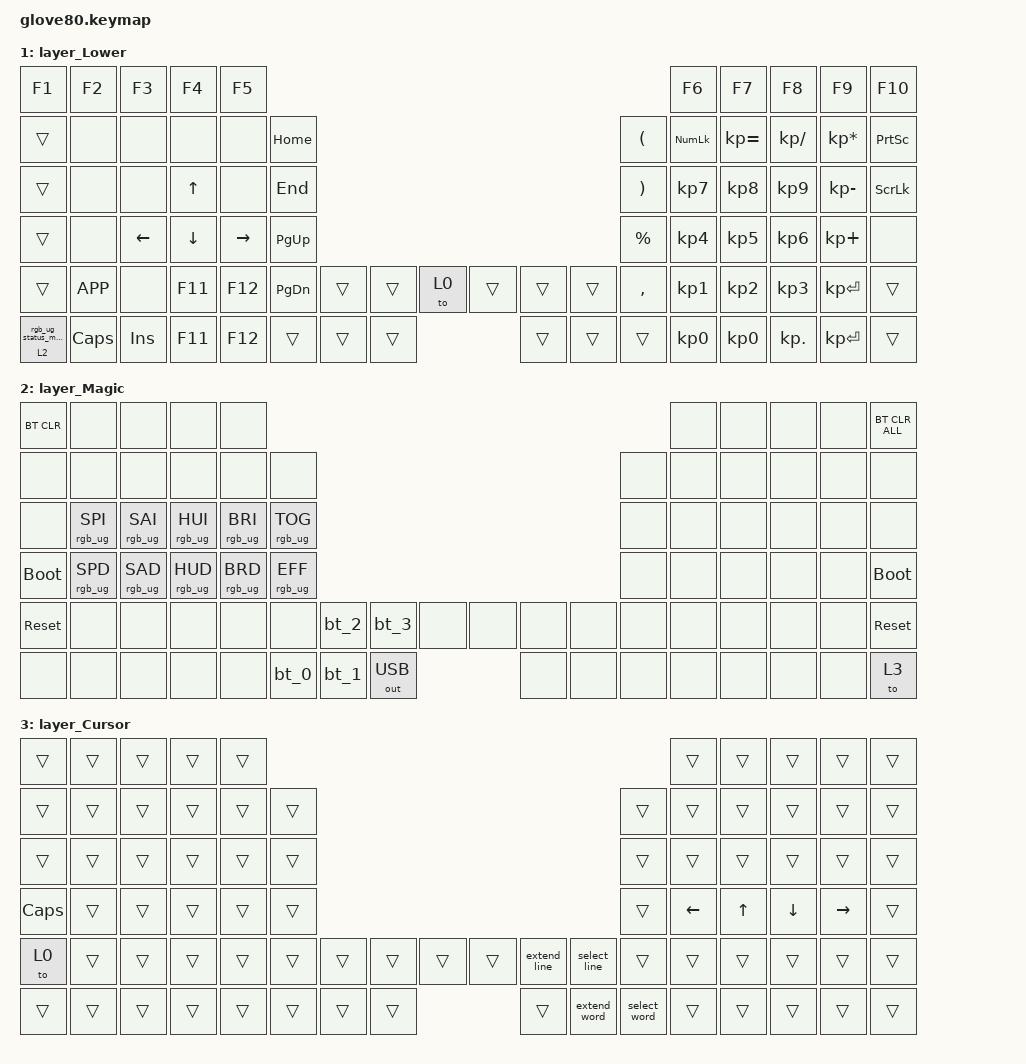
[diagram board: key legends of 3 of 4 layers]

/*
 * Copyright (c) 2020 The ZMK Contributors
 * Copyright (c) 2022 Innaworks Development Limited, trading as MoErgo
 *
 * SPDX-License-Identifier: MIT
 */


/* THIS FILE WAS GENERATED BY GLOVE80 LAYOUT EDITOR
 *
 * This file was generated automatically. You may or may not want to
 * edit it directly.
 */

#include <behaviors.dtsi>
/* Include all behaviour includes needed by system behaviors/macros */
#include <dt-bindings/zmk/outputs.h>

/* Include behaviour includes needed by key binds - automatically generated */
#include <dt-bindings/zmk/keys.h>
#include <dt-bindings/zmk/ext_power.h>
#include <dt-bindings/zmk/bt.h>
#include <dt-bindings/zmk/outputs.h>
#include <dt-bindings/zmk/rgb.h>


    /* Custom Defined Behaviors */
    //
    // Glove80 key positions index for positional hold-tap
    // https://discord.com/channels/877392805654306816/937645688244826154/1066713913351221248
    // https://media.discordapp.net/attachments/937645688244826154/1066713913133121556/image.png
    //
    // |------------------------|------------------------|
    // | LEFT_HAND_KEYS         |        RIGHT_HAND_KEYS |
    // |                        |                        |
    // |  0  1  2  3  4         |          5  6  7  8  9 |
    // | 10 11 12 13 14 15      |      16 17 18 19 20 21 |
    // | 22 23 24 25 26 27      |      28 29 30 31 32 33 |
    // | 34 35 36 37 38 39      |      40 41 42 43 44 45 |
    // | 46 47 48 49 50 51      |      58 59 60 61 62 63 |
    // | 64 65 66 67 68         |         75 76 77 78 79 |
    // |                69 52   |   57 74                |
    // |                 70 53  |  56 73                 |
    // |                  71 54 | 55 72                  |
    // |------------------------|------------------------|
    //
    //
    #define LEFT_HAND_KEYS      \
          0  1  2  3  4         \
         10 11 12 13 14 15      \
         22 23 24 25 26 27      \
         34 35 36 37 38 39      \
         46 47 48 49 50 51      \
         64 65 66 67 68
    #define                              RIGHT_HAND_KEYS \
                                           5  6  7  8  9 \
                                       16 17 18 19 20 21 \
                                       28 29 30 31 32 33 \
                                       40 41 42 43 44 45 \
                                       58 59 60 61 62 63 \
                                          75 76 77 78 79
    #define THUMB_KEYS          \
                        69 52       57 74                \
                         70 53     56 73                 \
                          71 54   55 72

/ {
combos {
    compatible = "zmk,combos";
    combo_space {
        timeout-ms = <50>;
        key-positions = <69 70>;
        bindings = <&kp SPACE>;
    };
    combo_enter {
        timeout-ms = <50>;
        key-positions = <70 71>;
        bindings = <&kp ENTER>;
    };
    combo_tab {
        timeout-ms = <50>;
        key-positions = <52 69>;
        bindings = <&kp TAB>;
    };
};
behaviors {
    magic: magic_hold_tap {
        compatible = "zmk,behavior-hold-tap";
        label = "MAGIC_HOLD_TAP";
        #binding-cells = <2>;
        flavor = "tap-preferred";
        tapping-term-ms = <200>;
        bindings = <&mo>, <&rgb_ug_status_macro>;
    };
            // For the "layer" key, it'd nice to be able to use it as either a shift or a toggle.
        // Configure it as a tap dance, so the first tap (or hold) is a &mo and the second tap is a &to
        lower: tap_dance_0 {
            compatible = "zmk,behavior-tap-dance";
            label = "LAYER_TAP_DANCE";
            #binding-cells = <0>;
            tapping-term-ms = <200>;
            bindings = <&mo 1>, <&to 1>;
        };

gqt2: global-quick-tap2 {
    compatible = "zmk,behavior-hold-tap";
    flavor = "tap-preferred";
    label = "HOME_ROW_MODS_PINKY_GUI2";
    #binding-cells = <2>;
    bindings = <&gravey>, <&kp>;
    tapping-term-ms = <320>; // extra delay
    quick-tap-ms = <160>;
    global-quick-tap;
};

    behavior_caps_word {
        continue-list = <UNDERSCORE MINUS BACKSPACE DELETE N1 N2 N3 N4 N5 N6 N7 N8 N9 N0>;
    };

    cappy: caps_word_lock {
        compatible = "zmk,behavior-mod-morph";
        label = "CAPS_WORD_LOCK";
        #binding-cells = <0>;
        bindings = <&caps_word>, <&kp CAPSLOCK>;
        mods = <(MOD_LSFT|MOD_RSFT)>;
    };

// Miryoku home row mods and thumb key layers
// https://sunaku.github.io/home-row-mods.html
    homey_left: home_row_mods_left_hand {
        compatible = "zmk,behavior-hold-tap";
        flavor = "tap-preferred";
        label = "HOME_ROW_MODS_LEFT_HAND";
        #binding-cells = <2>;
        bindings = <&kp>, <&kp>;
        hold-trigger-key-positions = <RIGHT_HAND_KEYS THUMB_KEYS>;
        hold-trigger-on-release;
        tapping-term-ms = <250>;
        quick-tap-ms = <175>;
        global-quick-tap-ms = <150>;
    };

    homey_right: home_row_mods_right_hand {
        compatible = "zmk,behavior-hold-tap";
        flavor = "tap-preferred";
        label = "HOME_ROW_MODS_RIGHT_HAND";
        #binding-cells = <2>;
        bindings = <&kp>, <&kp>;
        hold-trigger-key-positions = <LEFT_HAND_KEYS THUMB_KEYS>;
        hold-trigger-on-release;
        tapping-term-ms = <250>;
        quick-tap-ms = <175>;
        global-quick-tap-ms = <150>;
    };



    index_left: home_row_mods_left_index_shift {
        compatible = "zmk,behavior-hold-tap";
        flavor = "tap-preferred";
        label = "HOME_ROW_MODS_LEFT_INDEX_SHIFT";
        #binding-cells = <2>;
        bindings = <&kp>, <&kp>;
        hold-trigger-key-positions = <RIGHT_HAND_KEYS THUMB_KEYS>;
        hold-trigger-on-release;
        tapping-term-ms = <200>;
        quick-tap-ms = <160>;
        //global-quick-tap; // no typing streak
    };

    index_right: home_row_mods_right_index_shift {
        compatible = "zmk,behavior-hold-tap";
        flavor = "tap-preferred";
        label = "HOME_ROW_MODS_RIGHT_INDEX_SHIFT";
        #binding-cells = <2>;
        bindings = <&kp>, <&kp>;
        hold-trigger-key-positions = <LEFT_HAND_KEYS THUMB_KEYS>;
        hold-trigger-on-release;
        tapping-term-ms = <200>;
        quick-tap-ms = <160>;
        //global-quick-tap; // no typing streak
    };

    pinky: home_row_mods_pinky_gui {
        compatible = "zmk,behavior-hold-tap";
        flavor = "tap-preferred";
        label = "HOME_ROW_MODS_PINKY_GUI";
        #binding-cells = <2>;
        bindings = <&kp>, <&kp>;
        tapping-term-ms = <320>; // extra delay
        quick-tap-ms = <175>;
        global-quick-tap-ms = <150>;
    };

    pinky_left: home_row_mods_left_pinky_gui {
        compatible = "zmk,behavior-hold-tap";
        flavor = "tap-preferred";
        label = "HOME_ROW_MODS_LEFT_PINKY_GUI";
        #binding-cells = <2>;
        bindings = <&kp>, <&kp>;
        hold-trigger-key-positions = <RIGHT_HAND_KEYS THUMB_KEYS>;
        hold-trigger-on-release;
        tapping-term-ms = <320>; // extra delay
        quick-tap-ms = <175>;
        global-quick-tap-ms = <150>;
    };

    pinky_right: home_row_mods_right_pinky_gui {
        compatible = "zmk,behavior-hold-tap";
        flavor = "tap-preferred";
        label = "HOME_ROW_MODS_RIGHT_PINKY_GUI";
        #binding-cells = <2>;
        bindings = <&kp>, <&kp>;
        hold-trigger-key-positions = <LEFT_HAND_KEYS THUMB_KEYS>;
        hold-trigger-on-release;
        tapping-term-ms = <320>; // extra delay
        quick-tap-ms = <175>;
        global-quick-tap-ms = <150>;
    };

    thumb: miryoku_thumb_layer {
        compatible = "zmk,behavior-hold-tap";
        label = "MIRYOKU_LAYER_TAP_WITH_REPEAT";
        #binding-cells = <2>;
        flavor = "balanced"; // faster hold-tap
        tapping-term-ms = <200>;
        quick-tap-ms = <200>; // enable repeat
        bindings = <&mo>, <&kp>;
    };
};

macros {


        rgb_ug_status_macro: rgb_ug_status_macro_0 {
            label = "RGB_UG_STATUS";
            compatible = "zmk,behavior-macro";
            #binding-cells = <0>;
            bindings
                = <&rgb_ug RGB_STATUS>;
        };
        bt_0: bt_profile_macro_0 {
            label = "BT_0";
            compatible = "zmk,behavior-macro";
            #binding-cells = <0>;
            bindings
                = <&out OUT_BLE>,
                  <&bt BT_SEL 0>;
        };
        bt_1: bt_profile_macro_1 {
            label = "BT_1";
            compatible = "zmk,behavior-macro";
            #binding-cells = <0>;
            bindings
                = <&out OUT_BLE>,
                  <&bt BT_SEL 1>;
        };
        bt_2: bt_profile_macro_2 {
            label = "BT_2";
            compatible = "zmk,behavior-macro";
            #binding-cells = <0>;
            bindings
                = <&out OUT_BLE>,
                  <&bt BT_SEL 2>;
        };

        bt_3: bt_profile_macro_3 {
            label = "BT_3";
            compatible = "zmk,behavior-macro";
            #binding-cells = <0>;
            bindings
                = <&out OUT_BLE>,
                  <&bt BT_SEL 3>;
        };


    gravey: gravey {
wait-ms = <10>;
        label = "gravey";
        compatible = "zmk,behavior-macro";
        #binding-cells = <0>;
        bindings
            = <&macro_tap &kp GRAVE &kp GRAVE &kp GRAVE &kp SPACE>;
    };

    // Approximation of Pascal Getreuer's SelectWord feature in QMK
    // https://getreuer.info/posts/keyboards/select-word/index.html
    select_word: select_word {
        compatible = "zmk,behavior-macro";
        label = "select_word";
        #binding-cells = <0>;
        tap-ms = <0>;
        wait-ms = <0>;
        bindings
        = <&macro_tap &kp LC(RIGHT)>
        , <&macro_wait_time 1> // let cursor move to the next word!
        , <&macro_tap &kp LC(LEFT) &kp LC(LS(RIGHT))>
        ;
    };
    extend_word: extend_word {
        compatible = "zmk,behavior-macro";
        label = "extend_word";
        #binding-cells = <0>;
        tap-ms = <0>;
        wait-ms = <0>;
        bindings
        = <&macro_tap &kp LC(LS(RIGHT))>
        ;
    };
    select_line: select_line {
        compatible = "zmk,behavior-macro";
        label = "select_line";
        #binding-cells = <0>;
        tap-ms = <0>;
        wait-ms = <0>;
        bindings
        = <&macro_tap &kp HOME &kp LS(END)>
        ;
    };
    extend_line: extend_line {
        compatible = "zmk,behavior-macro";
        label = "extend_line";
        #binding-cells = <0>;
        tap-ms = <0>;
        wait-ms = <0>;
        bindings
        = <&macro_tap &kp LS(DOWN) &kp LS(END)>
        ;
    };
};


    /* Automatically generated keymap */
    keymap {
        compatible = "zmk,keymap";


        layer_Base {
            bindings = <
        &kp C_BRI_DN         &kp C_BRI_UP          &kp C_PREV          &kp C_NEXT              &kp C_PP                                                                                              &kp C_MUTE             &kp C_VOL_DN           &kp C_VOL_UP                    &none      &kp PAUSE_BREAK
           &kp MINUS               &kp N1              &kp N2              &kp N3                &kp N4  &kp N5                                                                   &kp N6                 &kp N7                   &kp N8                 &kp N9                   &kp N0            &kp EQUAL
             &kp TAB                &kp Q               &kp W               &kp E                 &kp R   &kp T                                                                    &kp Y                  &kp U                    &kp I                  &kp O                    &kp P             &kp BSLH
              &cappy  &pinky_left LCTRL A  &homey_left LALT S  &homey_left LGUI D  &index_left LSHIFT F   &kp G                                                                    &kp H  &index_right LSHIFT J      &homey_right LGUI K    &homey_right LALT L  &pinky_right LCTRL SEMI  &pinky CAPSLOCK SQT
 &gqt2 &gravey GRAVE                &kp Z  &homey_left RALT X  &homey_left RGUI C                 &kp V   &kp B  &thumb 3 ESC   &kp UP  &kp DOWN  &kp LEFT  &kp RIGHT    &kp RET   &kp N                  &kp M  &homey_right RGUI COMMA  &homey_right RALT DOT                 &kp FSLH            &kp PG_UP
          &magic 2 0             &kp HOME             &kp END           &kp LG(C)             &kp LG(V)              &kp BSPC  &kp DEL    &lower    &lower    &kp TAB  &kp SPACE                        &kp INS                    &none               &kp LBKT                 &kp RBKT            &kp PG_DN
            >;
        };

        layer_Lower {
            bindings = <
     &kp F1     &kp F2          &kp F3          &kp F4           &kp F5                                                                                        &kp F6        &kp F7        &kp F8           &kp F9          &kp F10
     &trans      &none           &none           &none            &none   &kp HOME                                                   &kp LEFT_PARENTHESIS  &kp KP_NUM  &kp KP_EQUAL  &kp KP_SLASH  &kp KP_MULTIPLY  &kp PRINTSCREEN
     &trans      &none           &none    &kp UP_ARROW            &none    &kp END                                                  &kp RIGHT_PARENTHESIS   &kp KP_N7     &kp KP_N8     &kp KP_N9     &kp KP_MINUS   &kp SCROLLLOCK
     &trans      &none  &kp LEFT_ARROW  &kp DOWN_ARROW  &kp RIGHT_ARROW  &kp PG_UP                                                            &kp PERCENT   &kp KP_N4     &kp KP_N5     &kp KP_N6      &kp KP_PLUS            &none
     &trans  &kp K_APP           &none         &kp F11          &kp F12  &kp PG_DN  &trans  &trans   &to 0  &trans  &trans  &trans              &kp COMMA   &kp KP_N1     &kp KP_N2     &kp KP_N3     &kp KP_ENTER           &trans
 &magic 2 0   &kp CAPS         &kp INS         &kp F11          &kp F12             &trans  &trans  &trans  &trans  &trans  &trans                          &kp KP_N0     &kp KP_N0    &kp KP_DOT     &kp KP_ENTER           &trans
            >;
        };

        layer_Magic {
            bindings = <
  &bt BT_CLR            &none            &none            &none            &none                                                                                  &none   &none   &none   &none  &bt BT_CLR_ALL
       &none            &none            &none            &none            &none            &none                                                         &none   &none   &none   &none   &none           &none
       &none  &rgb_ug RGB_SPI  &rgb_ug RGB_SAI  &rgb_ug RGB_HUI  &rgb_ug RGB_BRI  &rgb_ug RGB_TOG                                                         &none   &none   &none   &none   &none           &none
 &bootloader  &rgb_ug RGB_SPD  &rgb_ug RGB_SAD  &rgb_ug RGB_HUD  &rgb_ug RGB_BRD  &rgb_ug RGB_EFF                                                         &none   &none   &none   &none   &none     &bootloader
      &sys_reset            &none            &none            &none            &none            &none   &bt_2   &bt_3         &none   &none   &none   &none   &none   &none   &none   &none   &none          &sys_reset
       &none            &none            &none            &none            &none                    &bt_0   &bt_1  &out OUT_USB   &none   &none   &none           &none   &none   &none   &none           &to 3
            >;
        };

        layer_Cursor {
            bindings = <
   &trans  &trans  &trans  &trans  &trans                                                                                &trans  &trans    &trans     &trans  &trans
   &trans  &trans  &trans  &trans  &trans  &trans                                                              &trans    &trans  &trans    &trans     &trans  &trans
   &trans  &trans  &trans  &trans  &trans  &trans                                                              &trans    &trans  &trans    &trans     &trans  &trans
 &kp CAPS  &trans  &trans  &trans  &trans  &trans                                                              &trans  &kp LEFT  &kp UP  &kp DOWN  &kp RIGHT  &trans
    &to 0  &trans  &trans  &trans  &trans  &trans  &trans  &trans  &trans  &trans  &extend_line  &select_line  &trans    &trans  &trans    &trans     &trans  &trans
   &trans  &trans  &trans  &trans  &trans          &trans  &trans  &trans  &trans  &extend_word  &select_word            &trans  &trans    &trans     &trans  &trans
            >;
        };

    };
};
